# iospear600 register map
Registers from a debugger description file.
Registers are 32-bit, access not given, no defined reset value unless marked. A register's access mark holds for its fields unless they carry their own. Addresses are absolute; registers are grouped by the start of their names; lines under a group give offsets from that group; [hi:lo] are bit positions; {n}, {i} and the like mark numbered series; 'fields as' and 'values as' point back to an identical list; <NAME> marks a mode.

## PLL1
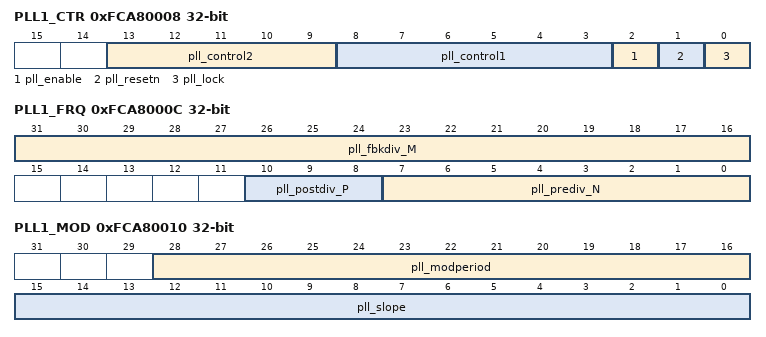
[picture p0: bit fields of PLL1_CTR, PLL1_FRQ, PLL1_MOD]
0xFCA80008 PLL1_CTR
  [13:9] pll_control2, [8:3] pll_control1, [2] pll_enable, [1] pll_resetn, [0] pll_lock
0xFCA8000C PLL1_FRQ
  [31:16] pll_fbkdiv_M, [10:8] pll_postdiv_P, [7:0] pll_prediv_N
0xFCA80010 PLL1_MOD
  [28:16] pll_modperiod, [15:0] pll_slope

## PLL2
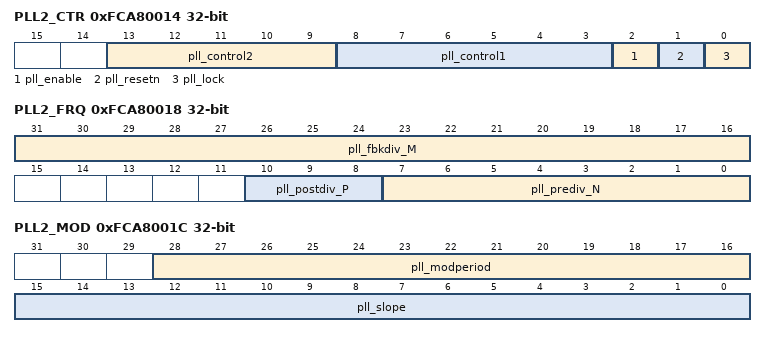
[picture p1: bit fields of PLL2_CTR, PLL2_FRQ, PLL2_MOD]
0xFCA80014 PLL2_CTR
  [13:9] pll_control2, [8:3] pll_control1, [2] pll_enable, [1] pll_resetn, [0] pll_lock
0xFCA80018 PLL2_FRQ
  [31:16] pll_fbkdiv_M, [10:8] pll_postdiv_P, [7:0] pll_prediv_N
0xFCA8001C PLL2_MOD
  [28:16] pll_modperiod, [15:0] pll_slope

## PERIP1
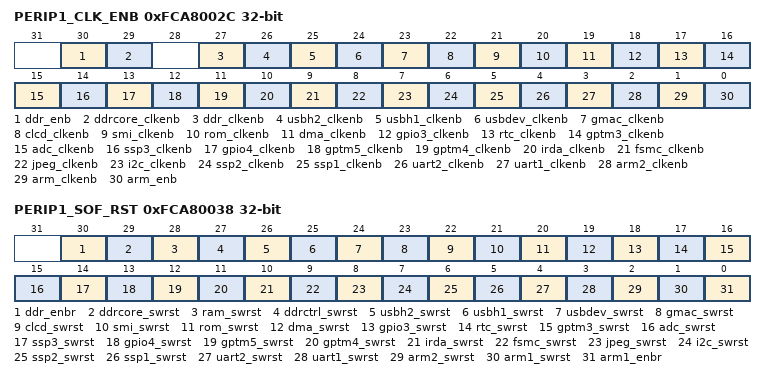
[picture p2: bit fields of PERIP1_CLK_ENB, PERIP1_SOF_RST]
0xFCA8002C PERIP1_CLK_ENB
  [30] ddr_enb, [29] ddrcore_clkenb, [27] ddr_clkenb, [26] usbh2_clkenb, [25] usbh1_clkenb, [24] usbdev_clkenb, [23] gmac_clkenb, [22] clcd_clkenb, [21] smi_clkenb, [20] rom_clkenb, [19] dma_clkenb, [18] gpio3_clkenb, [17] rtc_clkenb, [16] gptm3_clkenb, [15] adc_clkenb, [14] ssp3_clkenb, [13] gpio4_clkenb, [12] gptm5_clkenb, [11] gptm4_clkenb, [10] irda_clkenb, [9] fsmc_clkenb, [8] jpeg_clkenb, [7] i2c_clkenb, [6] ssp2_clkenb, [5] ssp1_clkenb, [4] uart2_clkenb, [3] uart1_clkenb, [2] arm2_clkenb, [1] arm_clkenb, [0] arm_enb
0xFCA80038 PERIP1_SOF_RST
  [30] ddr_enbr, [29] ddrcore_swrst, [28] ram_swrst, [27] ddrctrl_swrst, [26] usbh2_swrst, [25] usbh1_swrst, [24] usbdev_swrst, [23] gmac_swrst, [22] clcd_swrst, [21] smi_swrst, [20] rom_swrst, [19] dma_swrst, [18] gpio3_swrst, [17] rtc_swrst, [16] gptm3_swrst, [15] adc_swrst, [14] ssp3_swrst, [13] gpio4_swrst, [12] gptm5_swrst, [11] gptm4_swrst, [10] irda_swrst, [9] fsmc_swrst, [8] jpeg_swrst, [7] i2c_swrst, [6] ssp2_swrst, [5] ssp1_swrst, [4] uart2_swrst, [3] uart1_swrst, [2] arm2_swrst, [1] arm1_swrst, [0] arm1_enbr

## RAS
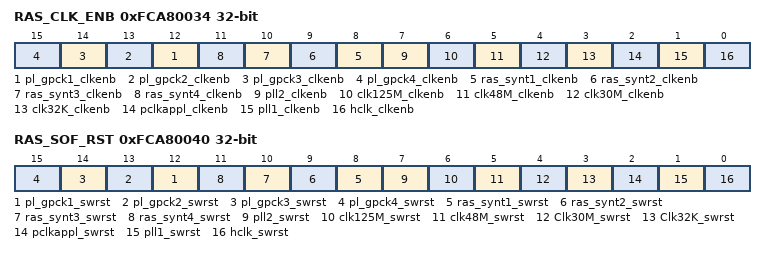
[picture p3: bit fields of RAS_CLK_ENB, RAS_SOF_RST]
0xFCA80034 RAS_CLK_ENB
  [n+11] pl_gpck{n}_clkenb (n=1..4), [n+7] ras_synt{n}_clkenb (n=1..4), [7] pll2_clkenb, [6] clk125M_clkenb, [5] clk48M_clkenb, [4] clk30M_clkenb, [3] clk32K_clkenb, [2] pclkappl_clkenb, [1] pll1_clkenb, [0] hclk_clkenb
0xFCA80040 RAS_SOF_RST
  [n+11] pl_gpck{n}_swrst (n=1..4), [n+7] ras_synt{n}_swrst (n=1..4), [7] pll2_swrst, [6] clk125M_swrst, [5] clk48M_swrst, [4] Clk30M_swrst, [3] Clk32K_swrst, [2] pclkappl_swrst, [1] pll1_swrst, [0] hclk_swrst

## EXPI
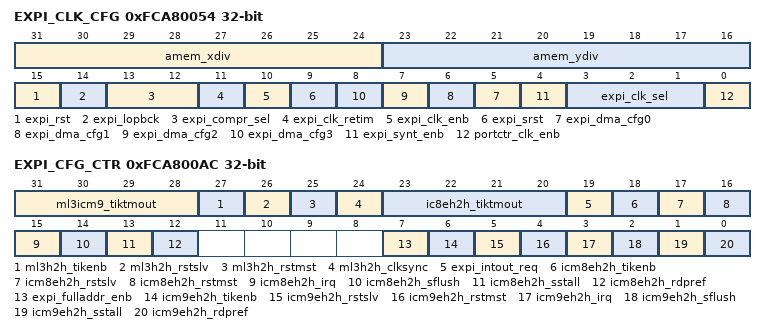
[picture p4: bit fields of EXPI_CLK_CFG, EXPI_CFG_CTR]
0xFCA80054 EXPI_CLK_CFG
  [31:24] amem_xdiv, [23:16] amem_ydiv, [15] expi_rst, [14] expi_lopbck, [13:12] expi_compr_sel, [11] expi_clk_retim, [10] expi_clk_enb, [9] expi_srst, [n+5] expi_dma_cfg{n} (n=0..3), [4] expi_synt_enb, [3:1] expi_clk_sel, [0] portctr_clk_enb
0xFCA800AC EXPI_CFG_CTR
  [31:28] ml3icm9_tiktmout, [27] ml3h2h_tikenb, [26] ml3h2h_rstslv, [25] ml3h2h_rstmst, [24] ml3h2h_clksync, [23:20] ic8eh2h_tiktmout, [19] expi_intout_req, [18] icm8eh2h_tikenb, [17] icm8eh2h_rstslv, [16] icm8eh2h_rstmst, [15] icm8eh2h_irq, [14] icm8eh2h_sflush, [13] icm8eh2h_sstall, [12] icm8eh2h_rdpref, [7] expi_fulladdr_enb, [6] icm9eh2h_tikenb, [5] icm9eh2h_rstslv, [4] icm9eh2h_rstmst, [3] icm9eh2h_irq, [2] icm9eh2h_sflush, [1] icm9eh2h_sstall, [0] icm9eh2h_rdpref
